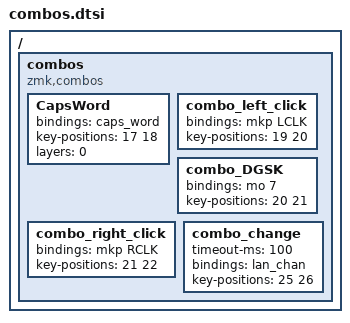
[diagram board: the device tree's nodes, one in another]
/* --- KEY ID LAYOUT --- */
// ╭──────┬──────┬──────┬──────┬──────┬──────╮  ╭──────┬──────┬──────┬──────┬──────┬──────╮
//    00     01     02     03    04      05        06     07     08     09     10     11
// ├──────┼──────┼──────┼──────┼──────┼──────┤  ├──────┼──────┼──────┼──────┼──────┼──────┤
//    12     13     14     15    16      17        18     19     20     21     22     23
// ├──────┼──────┼──────┼──────┼──────┼──────┤  ├──────┼──────┼──────┼──────┼──────┼──────┤
//    24     25     26     27    28      29        30     31     32     33     34     35
// ╰──────┴──────┴──────┼──────┼──────┼──────┤  ├──────┼──────┼──────┴──────┴──────┴──────╯
//                         36     37     38        39     40
//                      ╰──────┴──────┴──────╯  ╰──────┴──────╯

/ {
    combos {
        compatible = "zmk,combos";

        CapsWord {
            bindings = <&caps_word>;
            key-positions = <17 18>;
            layers = <0>;
        };
        
        combo_left_click {
            bindings = <&mkp LCLK>;
            key-positions = <19 20>;
        };

        combo_DGSK {
            bindings = <&mo 7>;
            key-positions = <20 21>;
        };

        combo_right_click {
            bindings = <&mkp RCLK>;
            key-positions = <21 22>;
        };

        combo_change {
            timeout-ms = <100>;
            bindings = <&lan_chan>;
            key-positions = <25 26>;
        };


    };
};
